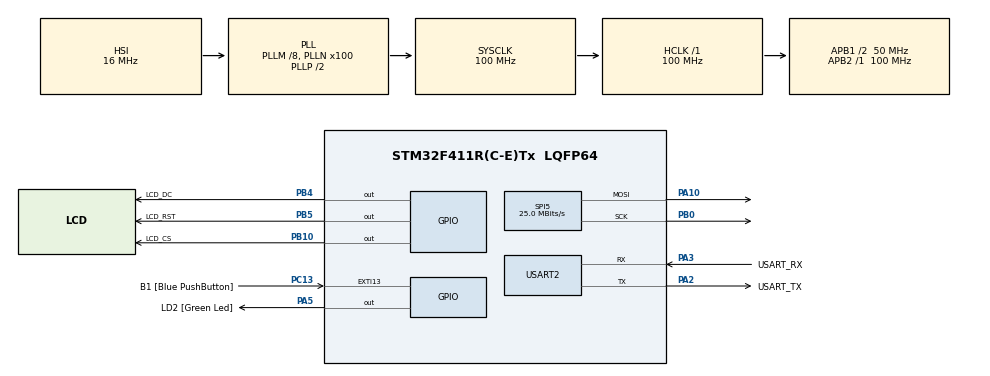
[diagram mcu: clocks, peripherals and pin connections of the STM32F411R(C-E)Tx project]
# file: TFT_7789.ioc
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Dma.Request0=SPI5_TX
Dma.SPI5_TX.0.Direction=DMA_MEMORY_TO_PERIPH
Dma.SPI5_TX.0.FIFOMode=DMA_FIFOMODE_DISABLE
Dma.SPI5_TX.0.Instance=DMA2_Stream4
Dma.SPI5_TX.0.MemDataAlignment=DMA_MDATAALIGN_BYTE
Dma.SPI5_TX.0.MemInc=DMA_MINC_ENABLE
Dma.SPI5_TX.0.Mode=DMA_NORMAL
Dma.SPI5_TX.0.PeriphDataAlignment=DMA_PDATAALIGN_BYTE
Dma.SPI5_TX.0.PeriphInc=DMA_PINC_DISABLE
Dma.SPI5_TX.0.Priority=DMA_PRIORITY_LOW
Mcu.Family=STM32F4
Mcu.Name=STM32F411R(C-E)Tx
Mcu.Package=LQFP64
NVIC.DMA2_Stream4_IRQn=true\:0\:0\:false\:false\:true\:false\:true\:true
NVIC.PriorityGroup=NVIC_PRIORITYGROUP_0
PA10.Mode=TX_Only_Simplex_Unidirect_Master
PA10.Signal=SPI5_MOSI
PA13.GPIO_Label=TMS
PA13.Mode=Serial_Wire
PA13.Signal=SYS_JTMS-SWDIO
PA14.GPIO_Label=TCK
PA14.Mode=Serial_Wire
PA14.Signal=SYS_JTCK-SWCLK
PA2.GPIO_Label=USART_TX
PA2.Mode=Asynchronous
PA2.Signal=USART2_TX
PA3.GPIO_Label=USART_RX
PA3.Mode=Asynchronous
PA3.Signal=USART2_RX
PA5.GPIO_Label=LD2 [Green Led]
PA5.Signal=GPIO_Output
PB0.Mode=TX_Only_Simplex_Unidirect_Master
PB0.Signal=SPI5_SCK
PB10.GPIO_Label=LCD_CS
PB10.GPIO_Speed=GPIO_SPEED_FREQ_VERY_HIGH
PB10.Signal=GPIO_Output
PB3.GPIO_Label=SWO
PB3.Signal=SYS_JTDO-SWO
PB4.GPIO_Label=LCD_DC
PB4.GPIO_Speed=GPIO_SPEED_FREQ_VERY_HIGH
PB4.Signal=GPIO_Output
PB5.GPIO_Label=LCD_RST
PB5.GPIO_Speed=GPIO_SPEED_FREQ_VERY_HIGH
PB5.Signal=GPIO_Output
PC13-ANTI_TAMP.GPIO_Label=B1 [Blue PushButton]
PC13-ANTI_TAMP.GPIO_ModeDefaultEXTI=GPIO_MODE_IT_FALLING
PC13-ANTI_TAMP.Signal=GPXTI13
PC14-OSC32_IN.Mode=LSE-External-Oscillator
PC14-OSC32_IN.Signal=RCC_OSC32_IN
PC15-OSC32_OUT.Mode=LSE-External-Oscillator
PC15-OSC32_OUT.Signal=RCC_OSC32_OUT
PH0\ -\ OSC_IN.Mode=HSE-External-Clock-Source
PH0\ -\ OSC_IN.Signal=RCC_OSC_IN
PH1\ -\ OSC_OUT.Mode=HSE-External-Clock-Source
PH1\ -\ OSC_OUT.Signal=RCC_OSC_OUT
ProjectManager.HeapSize=0x200
ProjectManager.StackSize=0x400
ProjectManager.TargetToolchain=STM32CubeIDE
RCC.48MHZClocksFreq_Value=50000000
RCC.AHBFreq_Value=100000000
RCC.APB1CLKDivider=RCC_HCLK_DIV2
RCC.APB1Freq_Value=50000000
RCC.APB1TimFreq_Value=100000000
RCC.APB2Freq_Value=100000000
RCC.APB2TimFreq_Value=100000000
RCC.CortexFreq_Value=100000000
RCC.FLatency-AdvancedSettings=FLASH_LATENCY_3
RCC.HCLKFreq_Value=100000000
RCC.HSE_VALUE=8000000
RCC.HSI_VALUE=16000000
RCC.PLLM=8
RCC.PLLN=100
RCC.SYSCLKFreq_VALUE=100000000
RCC.SYSCLKSource=RCC_SYSCLKSOURCE_PLLCLK
RCC.VCOOutputFreq_Value=200000000
SPI5.BaudRatePrescaler=SPI_BAUDRATEPRESCALER_4
SPI5.CLKPhase=SPI_PHASE_2EDGE
SPI5.CLKPolarity=SPI_POLARITY_HIGH
SPI5.CalculateBaudRate=25.0 MBits/s
SPI5.Direction=SPI_DIRECTION_2LINES
SPI5.Mode=SPI_MODE_MASTER
SPI5.VirtualType=VM_MASTER
USART2.VirtualMode=VM_ASYNC
board=NUCLEO-F411RE

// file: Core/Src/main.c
/* USER CODE BEGIN Header */
/**
  ******************************************************************************
  * @file           : main.c
  * @brief          : Main program body
  ******************************************************************************
  * @attention
  *
  * Copyright (c) 2026 STMicroelectronics.
  * All rights reserved.
  *
  * This software is licensed under terms that can be found in the LICENSE file
  * in the root directory of this software component.
  * If no LICENSE file comes with this software, it is provided AS-IS.
  *
  ******************************************************************************
  */
/* USER CODE END Header */
#include "main.h"
#include "dma.h"
#include "spi.h"
#include "usart.h"
#include "gpio.h"

void SystemClock_Config(void);
/* USER CODE BEGIN PFP */
void test_00(void);
/* USER CODE END PFP */

int main(void)
{

  /* USER CODE BEGIN 1 */
	// определяем где выполняется программа, и корректируем расположение
	// таблицы векторов
	uint32_t retPCasm(void);// небольшая функция для определения где выполняется программа в FLASH или RAM
	if ((retPCasm() & 0x20000000) != 0)
	{
		*((uint32_t *)0xe000ed08) = 0x20000000; /* FlagDebugInRAM=1;*/
	}

  /* USER CODE END 1 */

  /* MCU Configuration--------------------------------------------------------*/

  /* Reset of all peripherals, Initializes the Flash interface and the Systick. */
  HAL_Init();

  /* Configure the system clock */
  SystemClock_Config();

  /* Initialize all configured peripherals */
  MX_GPIO_Init();
  MX_DMA_Init();
  MX_SPI5_Init();
  MX_USART2_UART_Init();

  /* Infinite loop */
  /* USER CODE BEGIN WHILE */
  main_TFT_7789();

  while (1)
  {
    /* USER CODE END WHILE */

  }
}

void SystemClock_Config(void)
{
  RCC_OscInitTypeDef RCC_OscInitStruct = {0};
  RCC_ClkInitTypeDef RCC_ClkInitStruct = {0};

  /** Configure the main internal regulator output voltage
  */
  __HAL_RCC_PWR_CLK_ENABLE();
  __HAL_PWR_VOLTAGESCALING_CONFIG(PWR_REGULATOR_VOLTAGE_SCALE1);

  /** Initializes the RCC Oscillators according to the specified parameters
  * in the RCC_OscInitTypeDef structure.
  */
  RCC_OscInitStruct.OscillatorType = RCC_OSCILLATORTYPE_HSI;
  RCC_OscInitStruct.HSIState = RCC_HSI_ON;
  RCC_OscInitStruct.HSICalibrationValue = RCC_HSICALIBRATION_DEFAULT;
  RCC_OscInitStruct.PLL.PLLState = RCC_PLL_ON;
  RCC_OscInitStruct.PLL.PLLSource = RCC_PLLSOURCE_HSI;
  RCC_OscInitStruct.PLL.PLLM = 8;
  RCC_OscInitStruct.PLL.PLLN = 100;
  RCC_OscInitStruct.PLL.PLLP = RCC_PLLP_DIV2;
  RCC_OscInitStruct.PLL.PLLQ = 4;
  if (HAL_RCC_OscConfig(&RCC_OscInitStruct) != HAL_OK)
  {
    Error_Handler();
  }

  /** Initializes the CPU, AHB and APB buses clocks
  */
  RCC_ClkInitStruct.ClockType = RCC_CLOCKTYPE_HCLK|RCC_CLOCKTYPE_SYSCLK
                              |RCC_CLOCKTYPE_PCLK1|RCC_CLOCKTYPE_PCLK2;
  RCC_ClkInitStruct.SYSCLKSource = RCC_SYSCLKSOURCE_PLLCLK;
  RCC_ClkInitStruct.AHBCLKDivider = RCC_SYSCLK_DIV1;
  RCC_ClkInitStruct.APB1CLKDivider = RCC_HCLK_DIV2;
  RCC_ClkInitStruct.APB2CLKDivider = RCC_HCLK_DIV1;

  if (HAL_RCC_ClockConfig(&RCC_ClkInitStruct, FLASH_LATENCY_3) != HAL_OK)
  {
    Error_Handler();
  }
}

void Error_Handler(void)
{
  __disable_irq();
  while (1)
  {
  }
}
